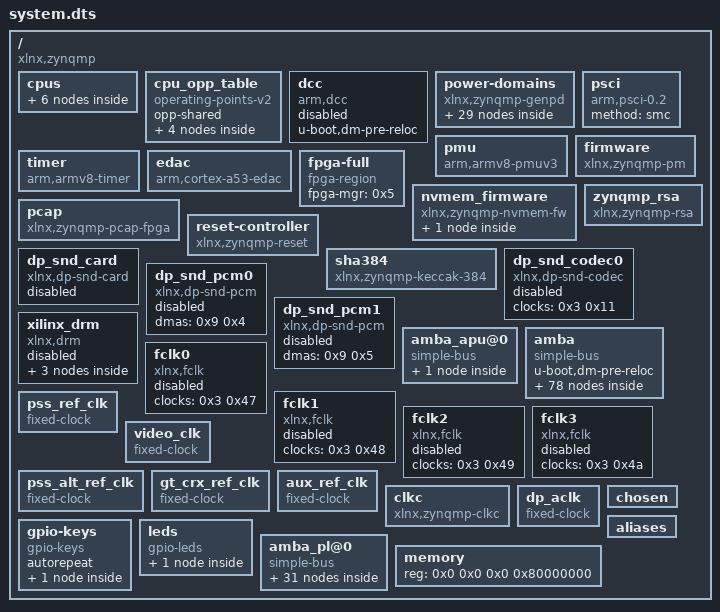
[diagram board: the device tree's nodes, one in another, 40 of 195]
/dts-v1/;

/ {
	compatible = "xlnx,zynqmp";
	#address-cells = <0x2>;
	#size-cells = <0x2>;

	cpus {
		#address-cells = <0x1>;
		#size-cells = <0x0>;

		cpu@0 {
			compatible = "arm,cortex-a53", "arm,armv8";
			device_type = "cpu";
			enable-method = "psci";
			operating-points-v2 = <0x1>;
			reg = <0x0>;
			cpu-idle-states = <0x2>;
			clocks = <0x3 0xa>;
		};

		cpu@1 {
			compatible = "arm,cortex-a53", "arm,armv8";
			device_type = "cpu";
			enable-method = "psci";
			reg = <0x1>;
			operating-points-v2 = <0x1>;
			cpu-idle-states = <0x2>;
		};

		cpu@2 {
			compatible = "arm,cortex-a53", "arm,armv8";
			device_type = "cpu";
			enable-method = "psci";
			reg = <0x2>;
			operating-points-v2 = <0x1>;
			cpu-idle-states = <0x2>;
		};

		cpu@3 {
			compatible = "arm,cortex-a53", "arm,armv8";
			device_type = "cpu";
			enable-method = "psci";
			reg = <0x3>;
			operating-points-v2 = <0x1>;
			cpu-idle-states = <0x2>;
		};

		idle-states {
			entry-method = "arm,psci";

			cpu-sleep-0 {
				compatible = "arm,idle-state";
				arm,psci-suspend-param = <0x40000000>;
				local-timer-stop;
				entry-latency-us = <0x12c>;
				exit-latency-us = <0x258>;
				min-residency-us = <0x2710>;
				linux,phandle = <0x2>;
				phandle = <0x2>;
			};
		};
	};

	cpu_opp_table {
		compatible = "operating-points-v2";
		opp-shared;
		linux,phandle = <0x1>;
		phandle = <0x1>;

		opp00 {
			opp-hz = <0x0 0x47868bf4>;
			opp-microvolt = <0xf4240>;
			clock-latency-ns = <0x7a120>;
		};

		opp01 {
			opp-hz = <0x0 0x23c345fa>;
			opp-microvolt = <0xf4240>;
			clock-latency-ns = <0x7a120>;
		};

		opp02 {
			opp-hz = <0x0 0x17d783fc>;
			opp-microvolt = <0xf4240>;
			clock-latency-ns = <0x7a120>;
		};

		opp03 {
			opp-hz = <0x0 0x11e1a2fd>;
			opp-microvolt = <0xf4240>;
			clock-latency-ns = <0x7a120>;
		};
	};

	dcc {
		compatible = "arm,dcc";
		status = "disabled";
		u-boot,dm-pre-reloc;
	};

	power-domains {
		compatible = "xlnx,zynqmp-genpd";

		pd-usb0 {
			#power-domain-cells = <0x0>;
			pd-id = <0x16>;
			linux,phandle = <0x38>;
			phandle = <0x38>;
		};

		pd-usb1 {
			#power-domain-cells = <0x0>;
			pd-id = <0x17>;
			linux,phandle = <0x3b>;
			phandle = <0x3b>;
		};

		pd-sata {
			#power-domain-cells = <0x0>;
			pd-id = <0x1c>;
			linux,phandle = <0x29>;
			phandle = <0x29>;
		};

		pd-spi0 {
			#power-domain-cells = <0x0>;
			pd-id = <0x23>;
			linux,phandle = <0x2e>;
			phandle = <0x2e>;
		};

		pd-spi1 {
			#power-domain-cells = <0x0>;
			pd-id = <0x24>;
			linux,phandle = <0x2f>;
			phandle = <0x2f>;
		};

		pd-uart0 {
			#power-domain-cells = <0x0>;
			pd-id = <0x21>;
			linux,phandle = <0x34>;
			phandle = <0x34>;
		};

		pd-uart1 {
			#power-domain-cells = <0x0>;
			pd-id = <0x22>;
			linux,phandle = <0x36>;
			phandle = <0x36>;
		};

		pd-eth0 {
			#power-domain-cells = <0x0>;
			pd-id = <0x1d>;
			linux,phandle = <0x14>;
			phandle = <0x14>;
		};

		pd-eth1 {
			#power-domain-cells = <0x0>;
			pd-id = <0x1e>;
			linux,phandle = <0x15>;
			phandle = <0x15>;
		};

		pd-eth2 {
			#power-domain-cells = <0x0>;
			pd-id = <0x1f>;
			linux,phandle = <0x16>;
			phandle = <0x16>;
		};

		pd-eth3 {
			#power-domain-cells = <0x0>;
			pd-id = <0x20>;
			linux,phandle = <0x17>;
			phandle = <0x17>;
		};

		pd-i2c0 {
			#power-domain-cells = <0x0>;
			pd-id = <0x25>;
			linux,phandle = <0x1c>;
			phandle = <0x1c>;
		};

		pd-i2c1 {
			#power-domain-cells = <0x0>;
			pd-id = <0x26>;
			linux,phandle = <0x20>;
			phandle = <0x20>;
		};

		pd-dp {
			#power-domain-cells = <0x0>;
			pd-id = <0x29>;
			linux,phandle = <0x3c>;
			phandle = <0x3c>;
		};

		pd-gdma {
			#power-domain-cells = <0x0>;
			pd-id = <0x2a>;
			linux,phandle = <0x10>;
			phandle = <0x10>;
		};

		pd-adma {
			#power-domain-cells = <0x0>;
			pd-id = <0x2b>;
			linux,phandle = <0x12>;
			phandle = <0x12>;
		};

		pd-ttc0 {
			#power-domain-cells = <0x0>;
			pd-id = <0x18>;
			linux,phandle = <0x30>;
			phandle = <0x30>;
		};

		pd-ttc1 {
			#power-domain-cells = <0x0>;
			pd-id = <0x19>;
			linux,phandle = <0x31>;
			phandle = <0x31>;
		};

		pd-ttc2 {
			#power-domain-cells = <0x0>;
			pd-id = <0x1a>;
			linux,phandle = <0x32>;
			phandle = <0x32>;
		};

		pd-ttc3 {
			#power-domain-cells = <0x0>;
			pd-id = <0x1b>;
			linux,phandle = <0x33>;
			phandle = <0x33>;
		};

		pd-sd0 {
			#power-domain-cells = <0x0>;
			pd-id = <0x27>;
			linux,phandle = <0x2b>;
			phandle = <0x2b>;
		};

		pd-sd1 {
			#power-domain-cells = <0x0>;
			pd-id = <0x28>;
			linux,phandle = <0x2c>;
			phandle = <0x2c>;
		};

		pd-nand {
			#power-domain-cells = <0x0>;
			pd-id = <0x2c>;
			linux,phandle = <0x13>;
			phandle = <0x13>;
		};

		pd-qspi {
			#power-domain-cells = <0x0>;
			pd-id = <0x2d>;
			linux,phandle = <0x26>;
			phandle = <0x26>;
		};

		pd-gpio {
			#power-domain-cells = <0x0>;
			pd-id = <0x2e>;
			linux,phandle = <0x1a>;
			phandle = <0x1a>;
		};

		pd-can0 {
			#power-domain-cells = <0x0>;
			pd-id = <0x2f>;
			linux,phandle = <0xc>;
			phandle = <0xc>;
		};

		pd-can1 {
			#power-domain-cells = <0x0>;
			pd-id = <0x30>;
			linux,phandle = <0xd>;
			phandle = <0xd>;
		};

		pd-pcie {
			#power-domain-cells = <0x0>;
			pd-id = <0x3b>;
			linux,phandle = <0x25>;
			phandle = <0x25>;
		};

		pd-gpu {
			#power-domain-cells = <0x0>;
			pd-id = <0x3a 0x14 0x15>;
			linux,phandle = <0x11>;
			phandle = <0x11>;
		};
	};

	pmu {
		compatible = "arm,armv8-pmuv3";
		interrupt-parent = <0x4>;
		interrupts = <0x0 0x8f 0x4 0x0 0x90 0x4 0x0 0x91 0x4 0x0 0x92 0x4>;
	};

	psci {
		compatible = "arm,psci-0.2";
		method = "smc";
	};

	firmware {
		compatible = "xlnx,zynqmp-pm";
		method = "smc";
		interrupt-parent = <0x4>;
		interrupts = <0x0 0x23 0x4>;
	};

	timer {
		compatible = "arm,armv8-timer";
		interrupt-parent = <0x4>;
		interrupts = <0x1 0xd 0xf08 0x1 0xe 0xf08 0x1 0xb 0xf08 0x1 0xa 0xf08>;
	};

	edac {
		compatible = "arm,cortex-a53-edac";
	};

	fpga-full {
		compatible = "fpga-region";
		fpga-mgr = <0x5>;
		#address-cells = <0x2>;
		#size-cells = <0x2>;
	};

	nvmem_firmware {
		compatible = "xlnx,zynqmp-nvmem-fw";
		#address-cells = <0x1>;
		#size-cells = <0x1>;

		soc_revision@0 {
			reg = <0x0 0x4>;
			linux,phandle = <0x27>;
			phandle = <0x27>;
		};
	};

	pcap {
		compatible = "xlnx,zynqmp-pcap-fpga";
		linux,phandle = <0x5>;
		phandle = <0x5>;
	};

	reset-controller {
		compatible = "xlnx,zynqmp-reset";
		#reset-cells = <0x1>;
		linux,phandle = <0x28>;
		phandle = <0x28>;
	};

	zynqmp_rsa {
		compatible = "xlnx,zynqmp-rsa";
	};

	sha384 {
		compatible = "xlnx,zynqmp-keccak-384";
	};

	dp_snd_card {
		compatible = "xlnx,dp-snd-card";
		status = "disabled";
		xlnx,dp-snd-pcm = <0x6 0x7>;
		xlnx,dp-snd-codec = <0x8>;
	};

	dp_snd_codec0 {
		compatible = "xlnx,dp-snd-codec";
		status = "disabled";
		clock-names = "aud_clk";
		clocks = <0x3 0x11>;
		linux,phandle = <0x8>;
		phandle = <0x8>;
	};

	dp_snd_pcm0 {
		compatible = "xlnx,dp-snd-pcm";
		status = "disabled";
		dmas = <0x9 0x4>;
		dma-names = "tx";
		linux,phandle = <0x6>;
		phandle = <0x6>;
	};

	dp_snd_pcm1 {
		compatible = "xlnx,dp-snd-pcm";
		status = "disabled";
		dmas = <0x9 0x5>;
		dma-names = "tx";
		linux,phandle = <0x7>;
		phandle = <0x7>;
	};

	xilinx_drm {
		compatible = "xlnx,drm";
		status = "disabled";
		xlnx,encoder-slave = <0xa>;
		xlnx,connector-type = "DisplayPort";
		xlnx,dp-sub = <0xb>;
		clocks = <0x3 0x10>;

		planes {
			xlnx,pixel-format = "rgb565";

			plane0 {
				dmas = <0x9 0x3>;
				dma-names = "dma0";
			};

			plane1 {
				dmas = <0x9 0x0 0x9 0x1 0x9 0x2>;
				dma-names = "dma0", "dma1", "dma2";
			};
		};
	};

	amba_apu@0 {
		compatible = "simple-bus";
		#address-cells = <0x2>;
		#size-cells = <0x1>;
		ranges = <0x0 0x0 0x0 0x0 0xffffffff>;

		interrupt-controller@f9010000 {
			compatible = "arm,gic-400", "arm,cortex-a15-gic";
			#interrupt-cells = <0x3>;
			reg = <0x0 0xf9010000 0x10000 0x0 0xf9020000 0x20000 0x0 0xf9040000 0x20000 0x0 0xf9060000 0x20000>;
			interrupt-controller;
			interrupt-parent = <0x4>;
			interrupts = <0x1 0x9 0xf04>;
			linux,phandle = <0x4>;
			phandle = <0x4>;
		};
	};

	amba {
		compatible = "simple-bus";
		u-boot,dm-pre-reloc;
		#address-cells = <0x2>;
		#size-cells = <0x2>;
		ranges;

		can@ff060000 {
			compatible = "xlnx,zynq-can-1.0";
			status = "disabled";
			clock-names = "can_clk", "pclk";
			reg = <0x0 0xff060000 0x0 0x1000>;
			interrupts = <0x0 0x17 0x4>;
			interrupt-parent = <0x4>;
			tx-fifo-depth = <0x40>;
			rx-fifo-depth = <0x40>;
			power-domains = <0xc>;
			clocks = <0x3 0x3f 0x3 0x1f>;
		};

		can@ff070000 {
			compatible = "xlnx,zynq-can-1.0";
			status = "disabled";
			clock-names = "can_clk", "pclk";
			reg = <0x0 0xff070000 0x0 0x1000>;
			interrupts = <0x0 0x18 0x4>;
			interrupt-parent = <0x4>;
			tx-fifo-depth = <0x40>;
			rx-fifo-depth = <0x40>;
			power-domains = <0xd>;
			clocks = <0x3 0x40 0x3 0x1f>;
		};

		cci@fd6e0000 {
			compatible = "arm,cci-400";
			reg = <0x0 0xfd6e0000 0x0 0x9000>;
			ranges = <0x0 0x0 0xfd6e0000 0x10000>;
			#address-cells = <0x1>;
			#size-cells = <0x1>;

			pmu@9000 {
				compatible = "arm,cci-400-pmu,r1";
				reg = <0x9000 0x5000>;
				interrupt-parent = <0x4>;
				interrupts = <0x0 0x7b 0x4 0x0 0x7b 0x4 0x0 0x7b 0x4 0x0 0x7b 0x4 0x0 0x7b 0x4>;
			};
		};

		dma@fd500000 {
			status = "okay";
			compatible = "xlnx,zynqmp-dma-1.0";
			reg = <0x0 0xfd500000 0x0 0x1000>;
			interrupt-parent = <0x4>;
			interrupts = <0x0 0x7c 0x4>;
			clock-names = "clk_main", "clk_apb";
			xlnx,bus-width = <0x80>;
			#stream-id-cells = <0x1>;
			iommus = <0xf 0x14e8>;
			power-domains = <0x10>;
			clocks = <0x3 0x13 0x3 0x1f>;
		};

		dma@fd510000 {
			status = "okay";
			compatible = "xlnx,zynqmp-dma-1.0";
			reg = <0x0 0xfd510000 0x0 0x1000>;
			interrupt-parent = <0x4>;
			interrupts = <0x0 0x7d 0x4>;
			clock-names = "clk_main", "clk_apb";
			xlnx,bus-width = <0x80>;
			#stream-id-cells = <0x1>;
			iommus = <0xf 0x14e9>;
			power-domains = <0x10>;
			clocks = <0x3 0x13 0x3 0x1f>;
		};

		dma@fd520000 {
			status = "okay";
			compatible = "xlnx,zynqmp-dma-1.0";
			reg = <0x0 0xfd520000 0x0 0x1000>;
			interrupt-parent = <0x4>;
			interrupts = <0x0 0x7e 0x4>;
			clock-names = "clk_main", "clk_apb";
			xlnx,bus-width = <0x80>;
			#stream-id-cells = <0x1>;
			iommus = <0xf 0x14ea>;
			power-domains = <0x10>;
			clocks = <0x3 0x13 0x3 0x1f>;
		};

		dma@fd530000 {
			status = "okay";
			compatible = "xlnx,zynqmp-dma-1.0";
			reg = <0x0 0xfd530000 0x0 0x1000>;
			interrupt-parent = <0x4>;
			interrupts = <0x0 0x7f 0x4>;
			clock-names = "clk_main", "clk_apb";
			xlnx,bus-width = <0x80>;
			#stream-id-cells = <0x1>;
			iommus = <0xf 0x14eb>;
			power-domains = <0x10>;
			clocks = <0x3 0x13 0x3 0x1f>;
		};

		dma@fd540000 {
			status = "okay";
			compatible = "xlnx,zynqmp-dma-1.0";
			reg = <0x0 0xfd540000 0x0 0x1000>;
			interrupt-parent = <0x4>;
			interrupts = <0x0 0x80 0x4>;
			clock-names = "clk_main", "clk_apb";
			xlnx,bus-width = <0x80>;
			#stream-id-cells = <0x1>;
			iommus = <0xf 0x14ec>;
			power-domains = <0x10>;
			clocks = <0x3 0x13 0x3 0x1f>;
		};

		dma@fd550000 {
			status = "okay";
			compatible = "xlnx,zynqmp-dma-1.0";
			reg = <0x0 0xfd550000 0x0 0x1000>;
			interrupt-parent = <0x4>;
			interrupts = <0x0 0x81 0x4>;
			clock-names = "clk_main", "clk_apb";
			xlnx,bus-width = <0x80>;
			#stream-id-cells = <0x1>;
			iommus = <0xf 0x14ed>;
			power-domains = <0x10>;
			clocks = <0x3 0x13 0x3 0x1f>;
		};

		dma@fd560000 {
			status = "okay";
			compatible = "xlnx,zynqmp-dma-1.0";
			reg = <0x0 0xfd560000 0x0 0x1000>;
			interrupt-parent = <0x4>;
			interrupts = <0x0 0x82 0x4>;
			clock-names = "clk_main", "clk_apb";
			xlnx,bus-width = <0x80>;
			#stream-id-cells = <0x1>;
			iommus = <0xf 0x14ee>;
			power-domains = <0x10>;
			clocks = <0x3 0x13 0x3 0x1f>;
		};

		dma@fd570000 {
			status = "okay";
			compatible = "xlnx,zynqmp-dma-1.0";
			reg = <0x0 0xfd570000 0x0 0x1000>;
			interrupt-parent = <0x4>;
			interrupts = <0x0 0x83 0x4>;
			clock-names = "clk_main", "clk_apb";
			xlnx,bus-width = <0x80>;
			#stream-id-cells = <0x1>;
			iommus = <0xf 0x14ef>;
			power-domains = <0x10>;
			clocks = <0x3 0x13 0x3 0x1f>;
		};

		gpu@fd4b0000 {
			status = "okay";
			compatible = "arm,mali-400", "arm,mali-utgard";
			reg = <0x0 0xfd4b0000 0x0 0x10000>;
			interrupt-parent = <0x4>;
			interrupts = <0x0 0x84 0x4 0x0 0x84 0x4 0x0 0x84 0x4 0x0 0x84 0x4 0x0 0x84 0x4 0x0 0x84 0x4>;
			interrupt-names = "IRQGP", "IRQGPMMU", "IRQPP0", "IRQPPMMU0", "IRQPP1", "IRQPPMMU1";
			clock-names = "gpu", "gpu_pp0", "gpu_pp1";
			power-domains = <0x11>;
			clocks = <0x3 0x18 0x3 0x19 0x3 0x1a>;
		};

		dma@ffa80000 {
			status = "okay";
			compatible = "xlnx,zynqmp-dma-1.0";
			clock-names = "clk_main", "clk_apb";
			reg = <0x0 0xffa80000 0x0 0x1000>;
			interrupt-parent = <0x4>;
			interrupts = <0x0 0x4d 0x4>;
			xlnx,bus-width = <0x40>;
			#stream-id-cells = <0x1>;
			power-domains = <0x12>;
			clocks = <0x3 0x44 0x3 0x1f>;
		};

		dma@ffa90000 {
			status = "okay";
			compatible = "xlnx,zynqmp-dma-1.0";
			clock-names = "clk_main", "clk_apb";
			reg = <0x0 0xffa90000 0x0 0x1000>;
			interrupt-parent = <0x4>;
			interrupts = <0x0 0x4e 0x4>;
			xlnx,bus-width = <0x40>;
			#stream-id-cells = <0x1>;
			power-domains = <0x12>;
			clocks = <0x3 0x44 0x3 0x1f>;
		};

		dma@ffaa0000 {
			status = "okay";
			compatible = "xlnx,zynqmp-dma-1.0";
			clock-names = "clk_main", "clk_apb";
			reg = <0x0 0xffaa0000 0x0 0x1000>;
			interrupt-parent = <0x4>;
			interrupts = <0x0 0x4f 0x4>;
			xlnx,bus-width = <0x40>;
			#stream-id-cells = <0x1>;
			power-domains = <0x12>;
			clocks = <0x3 0x44 0x3 0x1f>;
		};

		dma@ffab0000 {
			status = "okay";
			compatible = "xlnx,zynqmp-dma-1.0";
			clock-names = "clk_main", "clk_apb";
			reg = <0x0 0xffab0000 0x0 0x1000>;
			interrupt-parent = <0x4>;
			interrupts = <0x0 0x50 0x4>;
			xlnx,bus-width = <0x40>;
			#stream-id-cells = <0x1>;
			power-domains = <0x12>;
			clocks = <0x3 0x44 0x3 0x1f>;
		};

		dma@ffac0000 {
			status = "okay";
			compatible = "xlnx,zynqmp-dma-1.0";
			clock-names = "clk_main", "clk_apb";
			reg = <0x0 0xffac0000 0x0 0x1000>;
			interrupt-parent = <0x4>;
			interrupts = <0x0 0x51 0x4>;
			xlnx,bus-width = <0x40>;
			#stream-id-cells = <0x1>;
			power-domains = <0x12>;
			clocks = <0x3 0x44 0x3 0x1f>;
		};

		dma@ffad0000 {
			status = "okay";
			compatible = "xlnx,zynqmp-dma-1.0";
			clock-names = "clk_main", "clk_apb";
			reg = <0x0 0xffad0000 0x0 0x1000>;
			interrupt-parent = <0x4>;
			interrupts = <0x0 0x52 0x4>;
			xlnx,bus-width = <0x40>;
			#stream-id-cells = <0x1>;
			power-domains = <0x12>;
			clocks = <0x3 0x44 0x3 0x1f>;
		};

		dma@ffae0000 {
			status = "okay";
			compatible = "xlnx,zynqmp-dma-1.0";
			clock-names = "clk_main", "clk_apb";
			reg = <0x0 0xffae0000 0x0 0x1000>;
			interrupt-parent = <0x4>;
			interrupts = <0x0 0x53 0x4>;
			xlnx,bus-width = <0x40>;
			#stream-id-cells = <0x1>;
			power-domains = <0x12>;
			clocks = <0x3 0x44 0x3 0x1f>;
		};

		dma@ffaf0000 {
			status = "okay";
			compatible = "xlnx,zynqmp-dma-1.0";
			clock-names = "clk_main", "clk_apb";
			reg = <0x0 0xffaf0000 0x0 0x1000>;
			interrupt-parent = <0x4>;
			interrupts = <0x0 0x54 0x4>;
			xlnx,bus-width = <0x40>;
			#stream-id-cells = <0x1>;
			power-domains = <0x12>;
			clocks = <0x3 0x44 0x3 0x1f>;
		};

		memory-controller@fd070000 {
			compatible = "xlnx,zynqmp-ddrc-2.40a";
			reg = <0x0 0xfd070000 0x0 0x30000>;
			interrupt-parent = <0x4>;
			interrupts = <0x0 0x70 0x4>;
		};

		nand@ff100000 {
			compatible = "arasan,nfc-v3p10";
			status = "disabled";
			reg = <0x0 0xff100000 0x0 0x1000>;
			clock-names = "clk_sys", "clk_flash";
			interrupt-parent = <0x4>;
			interrupts = <0x0 0xe 0x4>;
			#address-cells = <0x1>;
			#size-cells = <0x0>;
			#stream-id-cells = <0x1>;
			iommus = <0xf 0x872>;
			power-domains = <0x13>;
			clocks = <0x3 0x3c 0x3 0x1f>;
		};

		ethernet@ff0b0000 {
			compatible = "cdns,zynqmp-gem";
			status = "okay";
			interrupt-parent = <0x4>;
			interrupts = <0x0 0x39 0x4 0x0 0x39 0x4>;
			reg = <0x0 0xff0b0000 0x0 0x1000>;
			clock-names = "pclk", "tx_clk", "hclk";
			#address-cells = <0x1>;
			#size-cells = <0x0>;
			#stream-id-cells = <0x1>;
			iommus = <0xf 0x874>;
			power-domains = <0x14>;
			clocks = <0x3 0x2d 0x3 0x2d 0x3 0x31>;
			phy-mode = "rgmii-id";
			xlnx,ptp-enet-clock = <0x0>;
			local-mac-address = [00 0a 35 00 22 01];
		};

		ethernet@ff0c0000 {
			compatible = "cdns,zynqmp-gem";
			status = "disabled";
			interrupt-parent = <0x4>;
			interrupts = <0x0 0x3b 0x4 0x0 0x3b 0x4>;
			reg = <0x0 0xff0c0000 0x0 0x1000>;
			clock-names = "pclk", "tx_clk", "hclk";
			#address-cells = <0x1>;
			#size-cells = <0x0>;
			#stream-id-cells = <0x1>;
			iommus = <0xf 0x875>;
			power-domains = <0x15>;
			clocks = <0x3 0x2e 0x3 0x2e 0x3 0x32>;
		};

		ethernet@ff0d0000 {
			compatible = "cdns,zynqmp-gem";
			status = "disabled";
			interrupt-parent = <0x4>;
			interrupts = <0x0 0x3d 0x4 0x0 0x3d 0x4>;
			reg = <0x0 0xff0d0000 0x0 0x1000>;
			clock-names = "pclk", "tx_clk", "hclk";
			#address-cells = <0x1>;
			#size-cells = <0x0>;
			#stream-id-cells = <0x1>;
			iommus = <0xf 0x876>;
			power-domains = <0x16>;
			clocks = <0x3 0x2f 0x3 0x2f 0x3 0x33>;
		};

		ethernet@ff0e0000 {
			compatible = "cdns,zynqmp-gem";
			status = "disabled";
			interrupt-parent = <0x4>;
			interrupts = <0x0 0x3f 0x4 0x0 0x3f 0x4>;
			reg = <0x0 0xff0e0000 0x0 0x1000>;
			clock-names = "pclk", "hclk", "tx_clk", "rx_clk";
			#address-cells = <0x1>;
			#size-cells = <0x0>;
			#stream-id-cells = <0x1>;
			iommus = <0xf 0x877>;
			power-domains = <0x17>;
			clocks = <0x3 0x1f 0x3 0x34 0x3 0x30 0x3 0x34>;
		};

		gpio@ff0a0000 {
			compatible = "xlnx,zynqmp-gpio-1.0";
			status = "disabled";
			#gpio-cells = <0x2>;
			interrupt-parent = <0x4>;
			interrupts = <0x0 0x10 0x4>;
			interrupt-controller;
			#interrupt-cells = <0x2>;
			reg = <0x0 0xff0a0000 0x0 0x1000>;
			gpio-controller;
			power-domains = <0x1a>;
			clocks = <0x3 0x1f>;
			emio-gpio-width = <0x20>;
			gpio-mask-high = <0x0>;
			gpio-mask-low = <0x5600>;
			linux,phandle = <0x1f>;
			phandle = <0x1f>;
		};

		i2c@ff020000 {
			compatible = "cdns,i2c-r1p14", "cdns,i2c-r1p10";
			status = "okay";
			interrupt-parent = <0x4>;
			interrupts = <0x0 0x11 0x4>;
			reg = <0x0 0xff020000 0x0 0x1000>;
			#address-cells = <0x1>;
			#size-cells = <0x0>;
			power-domains = <0x1c>;
			clocks = <0x3 0x3d>;
			clock-frequency = <0x171ec>;
		};

		i2c@ff030000 {
			compatible = "cdns,i2c-r1p14", "cdns,i2c-r1p10";
			status = "okay";
			interrupt-parent = <0x4>;
			interrupts = <0x0 0x12 0x4>;
			reg = <0x0 0xff030000 0x0 0x1000>;
			#address-cells = <0x1>;
			#size-cells = <0x0>;
			power-domains = <0x20>;
			clocks = <0x3 0x3e>;
			clock-frequency = <0x15c0c>;
		};

		memory-controller@ff960000 {
			compatible = "xlnx,zynqmp-ocmc-1.0";
			reg = <0x0 0xff960000 0x0 0x1000>;
			interrupt-parent = <0x4>;
			interrupts = <0x0 0xa 0x4>;
		};

		pcie@fd0e0000 {
			compatible = "xlnx,nwl-pcie-2.11";
			status = "disabled";
			#address-cells = <0x3>;
			#size-cells = <0x2>;
			#interrupt-cells = <0x1>;
			msi-controller;
			device_type = "pci";
			interrupt-parent = <0x4>;
			interrupts = <0x0 0x76 0x4 0x0 0x75 0x4 0x0 0x74 0x4 0x0 0x73 0x4 0x0 0x72 0x4>;
			interrupt-names = "misc", "dummy", "intx", "msi1", "msi0";
			msi-parent = <0x23>;
			reg = <0x0 0xfd0e0000 0x0 0x1000 0x0 0xfd480000 0x0 0x1000 0x80 0x0 0x0 0x1000000>;
			reg-names = "breg", "pcireg", "cfg";
			ranges = <0x2000000 0x0 0xe0000000 0x0 0xe0000000 0x0 0x10000000 0x43000000 0x6 0x0 0x6 0x0 0x2 0x0>;
			interrupt-map-mask = <0x0 0x0 0x0 0x7>;
			bus-range = <0x0 0xff>;
			interrupt-map = <0x0 0x0 0x0 0x1 0x24 0x1 0x0 0x0 0x0 0x2 0x24 0x2 0x0 0x0 0x0 0x3 0x24 0x3 0x0 0x0 0x0 0x4 0x24 0x4>;
			power-domains = <0x25>;
			clocks = <0x3 0x17>;
			linux,phandle = <0x23>;
			phandle = <0x23>;

			legacy-interrupt-controller {
				interrupt-controller;
				#address-cells = <0x0>;
				#interrupt-cells = <0x1>;
				linux,phandle = <0x24>;
				phandle = <0x24>;
			};
		};

		spi@ff0f0000 {
			u-boot,dm-pre-reloc;
			compatible = "xlnx,zynqmp-qspi-1.0";
			status = "okay";
			clock-names = "ref_clk", "pclk";
			interrupts = <0x0 0xf 0x4>;
			interrupt-parent = <0x4>;
			num-cs = <0x1>;
			reg = <0x0 0xff0f0000 0x0 0x1000 0x0 0xc0000000 0x0 0x8000000>;
			#address-cells = <0x1>;
			#size-cells = <0x0>;
			#stream-id-cells = <0x1>;
			iommus = <0xf 0x873>;
			power-domains = <0x26>;
			clocks = <0x3 0x35 0x3 0x1f>;
			is-dual = <0x1>;
			spi-rx-bus-width = <0x4>;
			spi-tx-bus-width = <0x4>;

			flash@0 {
				compatible = "mx66u1g45g", "micron,m25p80";
				#address-cells = <0x1>;
				#size-cells = <0x1>;
				reg = <0x0>;
				spi-tx-bus-width = <0x1>;
				spi-rx-bus-width = <0x4>;
				spi-max-frequency = <0x2faf080>;
			};
		};

		rtc@ffa60000 {
			compatible = "xlnx,zynqmp-rtc";
			status = "okay";
			reg = <0x0 0xffa60000 0x0 0x100>;
			interrupt-parent = <0x4>;
			interrupts = <0x0 0x1a 0x4 0x0 0x1b 0x4>;
			interrupt-names = "alarm", "sec";
			calibration = <0x8000>;
		};

		zynqmp_phy@fd400000 {
			compatible = "xlnx,zynqmp-psgtr";
			status = "okay";
			reg = <0x0 0xfd400000 0x0 0x40000 0x0 0xfd3d0000 0x0 0x1000 0x0 0xff5e0000 0x0 0x1000>;
			reg-names = "serdes", "siou", "lpd";
			nvmem-cells = <0x27>;
			nvmem-cell-names = "soc_revision";
			resets = <0x28 0x10 0x28 0x3b 0x28 0x3c 0x28 0x3d 0x28 0x3e 0x28 0x3f 0x28 0x40 0x28 0x3 0x28 0x1d 0x28 0x1e 0x28 0x1f 0x28 0x20>;
			reset-names = "sata_rst", "usb0_crst", "usb1_crst", "usb0_hibrst", "usb1_hibrst", "usb0_apbrst", "usb1_apbrst", "dp_rst", "gem0_rst", "gem1_rst", "gem2_rst", "gem3_rst";

			lane0 {
				#phy-cells = <0x4>;
			};

			lane1 {
				#phy-cells = <0x4>;
			};

			lane2 {
				#phy-cells = <0x4>;
				linux,phandle = <0x3a>;
				phandle = <0x3a>;
			};

			lane3 {
				#phy-cells = <0x4>;
				linux,phandle = <0x2a>;
				phandle = <0x2a>;
			};
		};

		ahci@fd0c0000 {
			compatible = "ceva,ahci-1v84";
			status = "disabled";
			reg = <0x0 0xfd0c0000 0x0 0x2000>;
			interrupt-parent = <0x4>;
			interrupts = <0x0 0x85 0x4>;
			power-domains = <0x29>;
			#stream-id-cells = <0x4>;
			iommus = <0xf 0x4c0 0xf 0x4c1 0xf 0x4c2 0xf 0x4c3>;
			clocks = <0x3 0x16>;
			ceva,p0-cominit-params = <0x18401828>;
			ceva,p0-comwake-params = <0x614080e>;
			ceva,p0-burst-params = <0x13084a06>;
			ceva,p0-retry-params = <0x96a43ffc>;
			ceva,p1-cominit-params = <0x18401828>;
			ceva,p1-comwake-params = <0x614080e>;
			ceva,p1-burst-params = <0x13084a06>;
			ceva,p1-retry-params = <0x96a43ffc>;
			phy-names = "sata-phy";
			phys = <0x2a 0x1 0x1 0x1 0x7735940>;
		};

		sdhci@ff160000 {
			u-boot,dm-pre-reloc;
			compatible = "xlnx,zynqmp-8.9a", "arasan,sdhci-8.9a";
			status = "disabled";
			interrupt-parent = <0x4>;
			interrupts = <0x0 0x30 0x4>;
			reg = <0x0 0xff160000 0x0 0x1000>;
			clock-names = "clk_xin", "clk_ahb";
			xlnx,device_id = <0x0>;
			#stream-id-cells = <0x1>;
			iommus = <0xf 0x870>;
			power-domains = <0x2b>;
			clocks = <0x3 0x36 0x3 0x1f>;
		};

		sdhci@ff170000 {
			u-boot,dm-pre-reloc;
			compatible = "xlnx,zynqmp-8.9a", "arasan,sdhci-8.9a";
			status = "disabled";
			interrupt-parent = <0x4>;
			interrupts = <0x0 0x31 0x4>;
			reg = <0x0 0xff170000 0x0 0x1000>;
			clock-names = "clk_xin", "clk_ahb";
			xlnx,device_id = <0x1>;
			#stream-id-cells = <0x1>;
			iommus = <0xf 0x871>;
			power-domains = <0x2c>;
			clocks = <0x3 0x37 0x3 0x1f>;
			clock-frequency = <0xbebc200>;
			xlnx,mio_bank = <0x1>;
		};

		pinctrl@ff180000 {
			compatible = "xlnx,pinctrl-zynqmp";
			status = "okay";
			reg = <0x0 0xff180000 0x0 0x1000>;
		};

		smmu@fd800000 {
			compatible = "arm,mmu-500";
			reg = <0x0 0xfd800000 0x0 0x20000>;
			#iommu-cells = <0x1>;
			status = "disabled";
			#global-interrupts = <0x1>;
			interrupt-parent = <0x4>;
			interrupts = <0x0 0x9b 0x4 0x0 0x9b 0x4 0x0 0x9b 0x4 0x0 0x9b 0x4 0x0 0x9b 0x4 0x0 0x9b 0x4 0x0 0x9b 0x4 0x0 0x9b 0x4 0x0 0x9b 0x4 0x0 0x9b 0x4 0x0 0x9b 0x4 0x0 0x9b 0x4 0x0 0x9b 0x4 0x0 0x9b 0x4 0x0 0x9b 0x4 0x0 0x9b 0x4 0x0 0x9b 0x4>;
			linux,phandle = <0xf>;
			phandle = <0xf>;
		};

		spi@ff040000 {
			compatible = "cdns,spi-r1p6";
			status = "okay";
			interrupt-parent = <0x4>;
			interrupts = <0x0 0x13 0x4>;
			reg = <0x0 0xff040000 0x0 0x1000>;
			clock-names = "ref_clk", "pclk";
			#address-cells = <0x1>;
			#size-cells = <0x0>;
			power-domains = <0x2e>;
			clocks = <0x3 0x3a 0x3 0x1f>;
			is-decoded-cs = <0x0>;
			num-cs = <0x3>;

			spidev@0 {
				compatible = "rohm,dh2228fv";
				reg = <0>;	/* chip select */
				spi-max-frequency = <12500000>;
				#address-cells = <1>;
				#size-cells = <1>;
			};
		
			spidev@1 {
				compatible = "rohm,dh2228fv";
				reg = <1>;	/* chip select */
				spi-max-frequency = <12500000>;
				#address-cells = <1>;
				#size-cells = <1>;
			};

			spidev@2 {
				compatible = "rohm,dh2228fv";
				reg = <2>;	/* chip select */
				spi-max-frequency = <12500000>;
				#address-cells = <1>;
				#size-cells = <1>;
			};

		};

		spi@ff050000 {
			compatible = "cdns,spi-r1p6";
			status = "okay";
			interrupt-parent = <0x4>;
			interrupts = <0x0 0x14 0x4>;
			reg = <0x0 0xff050000 0x0 0x1000>;
			clock-names = "ref_clk", "pclk";
			#address-cells = <0x1>;
			#size-cells = <0x0>;
			power-domains = <0x2f>;
			clocks = <0x3 0x3b 0x3 0x1f>;
			is-decoded-cs = <0x0>;
			num-cs = <0x2>;

			spidev@0 {
				compatible = "rohm,dh2228fv";
				reg = <0>;	/* chip select */
				spi-max-frequency = <12500000>;
				#address-cells = <1>;
				#size-cells = <1>;
			};
		
			spidev@1 {
				compatible = "rohm,dh2228fv";
				reg = <1>;	/* chip select */
				spi-max-frequency = <12500000>;
				#address-cells = <1>;
				#size-cells = <1>;
			};

		};

		fheth0_m@7FF00000 {
			compatible="fujitsu.fheth";
			reg = <0x0 0xA1000000 0x0 0x0001000 
			       0x0 0xA1010800 0x0 0x0000800 
			       0x0 0xA1024000 0x0 0x0004000
			       0x0 0xA1028000 0x0 0x0000100>;
			interrupt-parent = <0x4>;
			interrupts = <0x0 104 0x4>;
		};

		fheth0_s@7FF00000 {
			compatible="fujitsu.fheth";
			reg = <0x0 0xA1000000 0x0 0x0001000 
			       0x0 0xA1010000 0x0 0x0000800 
			       0x0 0xA1020000 0x0 0x0004000
			       0x0 0xA1028000 0x0 0x0000100>;
			interrupt-parent = <0x4>;
			interrupts = <0x0 106 0x4>;
		};

		timer@ff110000 {
			compatible = "cdns,ttc";
			status = "disabled";
			interrupt-parent = <0x4>;
			interrupts = <0x0 0x24 0x4 0x0 0x25 0x4 0x0 0x26 0x4>;
			reg = <0x0 0xff110000 0x0 0x1000>;
			timer-width = <0x20>;
			power-domains = <0x30>;
		};

		timer@ff120000 {
			compatible = "cdns,ttc";
			status = "disabled";
			interrupt-parent = <0x4>;
			interrupts = <0x0 0x27 0x4 0x0 0x28 0x4 0x0 0x29 0x4>;
			reg = <0x0 0xff120000 0x0 0x1000>;
			timer-width = <0x20>;
			power-domains = <0x31>;
		};

		timer@ff130000 {
			compatible = "cdns,ttc";
			status = "disabled";
			interrupt-parent = <0x4>;
			interrupts = <0x0 0x2a 0x4 0x0 0x2b 0x4 0x0 0x2c 0x4>;
			reg = <0x0 0xff130000 0x0 0x1000>;
			timer-width = <0x20>;
			power-domains = <0x32>;
		};

		timer@ff140000 {
			compatible = "cdns,ttc";
			status = "disabled";
			interrupt-parent = <0x4>;
			interrupts = <0x0 0x2d 0x4 0x0 0x2e 0x4 0x0 0x2f 0x4>;
			reg = <0x0 0xff140000 0x0 0x1000>;
			timer-width = <0x20>;
			power-domains = <0x33>;
		};

		serial@ff000000 {
			u-boot,dm-pre-reloc;
			compatible = "cdns,uart-r1p12", "xlnx,xuartps";
			status = "disabled";
			interrupt-parent = <0x4>;
			interrupts = <0x0 0x15 0x4>;
			reg = <0x0 0xff000000 0x0 0x1000>;
			clock-names = "uart_clk", "pclk";
			power-domains = <0x34>;
			clocks = <0x3 0x38 0x3 0x1f>;
		};

		serial@ff010000 {
			u-boot,dm-pre-reloc;
			compatible = "cdns,uart-r1p12", "xlnx,xuartps";
			status = "okay";
			interrupt-parent = <0x4>;
			interrupts = <0x0 0x16 0x4>;
			reg = <0x0 0xff010000 0x0 0x1000>;
			clock-names = "uart_clk", "pclk";
			power-domains = <0x36>;
			clocks = <0x3 0x39 0x3 0x1f>;
			device_type = "serial";
			port-number = <0x0>;
		};

		usb0@ff9d0000 {
			#address-cells = <0x2>;
			#size-cells = <0x2>;
			status = "disabled";
			compatible = "xlnx,zynqmp-dwc3";
			reg = <0x0 0xff9d0000 0x0 0x100>;
			clock-names = "bus_clk", "ref_clk";
			power-domains = <0x38>;
			ranges;
			nvmem-cells = <0x27>;
			nvmem-cell-names = "soc_revision";
			clocks = <0x3 0x20 0x3 0x22>;

			dwc3@fe200000 {
				compatible = "snps,dwc3";
				status = "disabled";
				reg = <0x0 0xfe200000 0x0 0x40000>;
				interrupt-parent = <0x4>;
				interrupts = <0x0 0x41 0x4 0x0 0x45 0x4>;
				#stream-id-cells = <0x1>;
				iommus = <0xf 0x860>;
				snps,quirk-frame-length-adjustment = <0x20>;
				snps,refclk_fladj;
				snps,enable_guctl1_resume_quirk;
				snps,enable_guctl1_ipd_quirk;
				snps,xhci-stream-quirk;
				dr_mode = "host";
				snps,usb3_lpm_capable;
				phy-names = "usb3-phy";
				phys = <0x3a 0x4 0x0 0x2 0x18cba80>;
			};
		};

		usb1@ff9e0000 {
			#address-cells = <0x2>;
			#size-cells = <0x2>;
			status = "disabled";
			compatible = "xlnx,zynqmp-dwc3";
			reg = <0x0 0xff9e0000 0x0 0x100>;
			clock-names = "bus_clk", "ref_clk";
			power-domains = <0x3b>;
			ranges;
			nvmem-cells = <0x27>;
			nvmem-cell-names = "soc_revision";
			clocks = <0x3 0x21 0x3 0x22>;

			dwc3@fe300000 {
				compatible = "snps,dwc3";
				status = "disabled";
				reg = <0x0 0xfe300000 0x0 0x40000>;
				interrupt-parent = <0x4>;
				interrupts = <0x0 0x46 0x4 0x0 0x4a 0x4>;
				#stream-id-cells = <0x1>;
				iommus = <0xf 0x861>;
				snps,quirk-frame-length-adjustment = <0x20>;
				snps,refclk_fladj;
				snps,enable_guctl1_resume_quirk;
				snps,enable_guctl1_ipd_quirk;
				snps,xhci-stream-quirk;
			};
		};

		watchdog@fd4d0000 {
			compatible = "cdns,wdt-r1p2";
			status = "disabled";
			interrupt-parent = <0x4>;
			interrupts = <0x0 0x71 0x1>;
			reg = <0x0 0xfd4d0000 0x0 0x1000>;
			timeout-sec = <0xa>;
			clocks = <0x3 0x4b>;
		};

		ams@ffa50000 {
			compatible = "xlnx,zynqmp-ams";
			status = "okay";
			interrupt-parent = <0x4>;
			interrupts = <0x0 0x38 0x4>;
			interrupt-names = "ams-irq";
			reg = <0x0 0xffa50000 0x0 0x800>;
			reg-names = "ams-base";
			#address-cells = <0x2>;
			#size-cells = <0x2>;
			#io-channel-cells = <0x1>;
			ranges;
			clocks = <0x3 0x46>;

			ams_ps@ffa50800 {
				compatible = "xlnx,zynqmp-ams-ps";
				status = "okay";
				reg = <0x0 0xffa50800 0x0 0x400>;
			};

			ams_pl@ffa50c00 {
				compatible = "xlnx,zynqmp-ams-pl";
				status = "okay";
				reg = <0x0 0xffa50c00 0x0 0x400>;
			};
		};

		dp@fd4a0000 {
			compatible = "xlnx,v-dp";
			status = "disabled";
			reg = <0x0 0xfd4a0000 0x0 0x1000>;
			interrupts = <0x0 0x77 0x4>;
			interrupt-parent = <0x4>;
			clock-names = "aclk", "aud_clk";
			power-domains = <0x3c>;
			xlnx,dp-version = "v1.2";
			xlnx,max-lanes = <0x2>;
			xlnx,max-link-rate = <0x83d60>;
			xlnx,max-bpc = <0x10>;
			xlnx,enable-ycrcb;
			xlnx,colormetry = "rgb";
			xlnx,bpc = <0x8>;
			xlnx,audio-chan = <0x2>;
			xlnx,dp-sub = <0xb>;
			xlnx,max-pclock-frequency = <0x493e0>;
			clocks = <0x3d 0x3 0x11>;
			linux,phandle = <0xa>;
			phandle = <0xa>;
		};

		dp_sub@fd4aa000 {
			compatible = "xlnx,dp-sub";
			status = "disabled";
			reg = <0x0 0xfd4aa000 0x0 0x1000 0x0 0xfd4ab000 0x0 0x1000 0x0 0xfd4ac000 0x0 0x1000>;
			reg-names = "blend", "av_buf", "aud";
			xlnx,output-fmt = "rgb";
			xlnx,vid-fmt = "yuyv";
			xlnx,gfx-fmt = "rgb565";
			power-domains = <0x3c>;
			linux,phandle = <0xb>;
			phandle = <0xb>;
		};

		dma@fd4c0000 {
			compatible = "xlnx,dpdma";
			status = "disabled";
			reg = <0x0 0xfd4c0000 0x0 0x1000>;
			interrupts = <0x0 0x7a 0x4>;
			interrupt-parent = <0x4>;
			clock-names = "axi_clk";
			power-domains = <0x3c>;
			dma-channels = <0x6>;
			#dma-cells = <0x1>;
			clocks = <0x3 0x14>;
			linux,phandle = <0x9>;
			phandle = <0x9>;

			dma-video0channel {
				compatible = "xlnx,video0";
			};

			dma-video1channel {
				compatible = "xlnx,video1";
			};

			dma-video2channel {
				compatible = "xlnx,video2";
			};

			dma-graphicschannel {
				compatible = "xlnx,graphics";
			};

			dma-audio0channel {
				compatible = "xlnx,audio0";
			};

			dma-audio1channel {
				compatible = "xlnx,audio1";
			};
		};
	};

	fclk0 {
		status = "disabled";
		compatible = "xlnx,fclk";
		clocks = <0x3 0x47>;
	};

	fclk1 {
		status = "disabled";
		compatible = "xlnx,fclk";
		clocks = <0x3 0x48>;
	};

	fclk2 {
		status = "disabled";
		compatible = "xlnx,fclk";
		clocks = <0x3 0x49>;
	};

	fclk3 {
		status = "disabled";
		compatible = "xlnx,fclk";
		clocks = <0x3 0x4a>;
	};

	pss_ref_clk {
		u-boot,dm-pre-reloc;
		compatible = "fixed-clock";
		#clock-cells = <0x0>;
		clock-frequency = <0x1fca055>;
		linux,phandle = <0x3e>;
		phandle = <0x3e>;
	};

	video_clk {
		u-boot,dm-pre-reloc;
		compatible = "fixed-clock";
		#clock-cells = <0x0>;
		clock-frequency = <0x19bfcc0>;
		linux,phandle = <0x3f>;
		phandle = <0x3f>;
	};

	pss_alt_ref_clk {
		u-boot,dm-pre-reloc;
		compatible = "fixed-clock";
		#clock-cells = <0x0>;
		clock-frequency = <0x0>;
		linux,phandle = <0x40>;
		phandle = <0x40>;
	};

	gt_crx_ref_clk {
		u-boot,dm-pre-reloc;
		compatible = "fixed-clock";
		#clock-cells = <0x0>;
		clock-frequency = <0x66ff300>;
		linux,phandle = <0x42>;
		phandle = <0x42>;
	};

	aux_ref_clk {
		u-boot,dm-pre-reloc;
		compatible = "fixed-clock";
		#clock-cells = <0x0>;
		clock-frequency = <0x19bfcc0>;
		linux,phandle = <0x41>;
		phandle = <0x41>;
	};

	clkc {
		u-boot,dm-pre-reloc;
		#clock-cells = <0x1>;
		compatible = "xlnx,zynqmp-clkc";
		clocks = <0x3e 0x3f 0x40 0x41 0x42>;
		clock-names = "pss_ref_clk", "video_clk", "pss_alt_ref_clk", "aux_ref_clk", "gt_crx_ref_clk";
		clock-output-names = "iopll", "rpll", "apll", "dpll", "vpll", "iopll_to_fpd", "rpll_to_fpd", "apll_to_lpd", "dpll_to_lpd", "vpll_to_lpd", "acpu", "acpu_half", "dbf_fpd", "dbf_lpd", "dbg_trace", "dbg_tstmp", "dp_video_ref", "dp_audio_ref", "dp_stc_ref", "gdma_ref", "dpdma_ref", "ddr_ref", "sata_ref", "pcie_ref", "gpu_ref", "gpu_pp0_ref", "gpu_pp1_ref", "topsw_main", "topsw_lsbus", "gtgref0_ref", "lpd_switch", "lpd_lsbus", "usb0_bus_ref", "usb1_bus_ref", "usb3_dual_ref", "usb0", "usb1", "cpu_r5", "cpu_r5_core", "csu_spb", "csu_pll", "pcap", "iou_switch", "gem_tsu_ref", "gem_tsu", "gem0_ref", "gem1_ref", "gem2_ref", "gem3_ref", "gem0_tx", "gem1_tx", "gem2_tx", "gem3_tx", "qspi_ref", "sdio0_ref", "sdio1_ref", "uart0_ref", "uart1_ref", "spi0_ref", "spi1_ref", "nand_ref", "i2c0_ref", "i2c1_ref", "can0_ref", "can1_ref", "can0", "can1", "dll_ref", "adma_ref", "timestamp_ref", "ams_ref", "pl0", "pl1", "pl2", "pl3", "wdt";
		linux,phandle = <0x3>;
		phandle = <0x3>;
	};

	dp_aclk {
		compatible = "fixed-clock";
		#clock-cells = <0x0>;
		clock-frequency = <0x5f5e100>;
		clock-accuracy = <0x64>;
		linux,phandle = <0x3d>;
		phandle = <0x3d>;
	};

	gpio-keys {
		compatible = "gpio-keys";
		#address-cells = <0x1>;
		#size-cells = <0x0>;
		autorepeat;

		sw19 {
			label = "sw19";
			gpios = <0x1f 0x16 0x0>;
			linux,code = <0x6c>;
			gpio-key,wakeup;
			autorepeat;
		};
	};

	leds {
		compatible = "gpio-leds";

		heartbeat_led {
			label = "heartbeat";
			gpios = <0x1f 0x17 0x0>;
			linux,default-trigger = "heartbeat";
		};
	};

	amba_pl@0 {
		#address-cells = <0x2>;
		#size-cells = <0x2>;
		compatible = "simple-bus";
		ranges;

		axi_bram_ctrl@a0e00000 {
			compatible = "xlnx,axi-bram-ctrl-4.1";
			reg = <0x0 0xa0e00000 0x0 0x10000>;
			xlnx,bram-addr-width = <0xc>;
			xlnx,bram-inst-mode = "EXTERNAL";
			xlnx,ecc = <0x0>;
			xlnx,ecc-onoff-reset-value = <0x0>;
			xlnx,ecc-type = <0x0>;
			xlnx,fault-inject = <0x0>;
			xlnx,memory-depth = <0x1000>;
			xlnx,rd-cmd-optimization = <0x0>;
			xlnx,read-latency = <0x1>;
			xlnx,s-axi-ctrl-addr-width = <0x20>;
			xlnx,s-axi-ctrl-data-width = <0x20>;
			xlnx,s-axi-id-width = <0x1>;
			xlnx,s-axi-supports-narrow-burst = <0x1>;
			xlnx,select-xpm = <0x1>;
			xlnx,single-port-bram = <0x1>;
		};

		axi_drp_bridge@a0f00000 {
			compatible = "xlnx,axi-drp-bridge-181226";
			reg = <0x0 0xa0f00000 0x0 0x1000>;
		};

		axi_drp_bridge@a0060000 {
			compatible = "xlnx,axi-drp-bridge-181226";
			reg = <0x0 0xa0060000 0x0 0x2000>;
		};

		axi_drp_bridge@a0050000 {
			compatible = "xlnx,axi-drp-bridge-181226";
			reg = <0x0 0xa0050000 0x0 0x10000>;
		};

		axi_bram_ctrl@a1020000 {
			compatible = "xlnx,axi-bram-ctrl-4.1";
			reg = <0x0 0xa1020000 0x0 0x10000>;
			xlnx,bram-addr-width = <0xd>;
			xlnx,bram-inst-mode = "EXTERNAL";
			xlnx,ecc = <0x0>;
			xlnx,ecc-onoff-reset-value = <0x0>;
			xlnx,ecc-type = <0x0>;
			xlnx,fault-inject = <0x0>;
			xlnx,memory-depth = <0x2000>;
			xlnx,rd-cmd-optimization = <0x0>;
			xlnx,read-latency = <0x1>;
			xlnx,s-axi-ctrl-addr-width = <0x20>;
			xlnx,s-axi-ctrl-data-width = <0x20>;
			xlnx,s-axi-id-width = <0x1>;
			xlnx,s-axi-supports-narrow-burst = <0x1>;
			xlnx,select-xpm = <0x1>;
			xlnx,single-port-bram = <0x1>;
		};

		axi_bram_ctrl@a1010000 {
			compatible = "xlnx,axi-bram-ctrl-4.1";
			reg = <0x0 0xa1010000 0x0 0x1000>;
			xlnx,bram-addr-width = <0xa>;
			xlnx,bram-inst-mode = "EXTERNAL";
			xlnx,ecc = <0x0>;
			xlnx,ecc-onoff-reset-value = <0x0>;
			xlnx,ecc-type = <0x0>;
			xlnx,fault-inject = <0x0>;
			xlnx,memory-depth = <0x400>;
			xlnx,rd-cmd-optimization = <0x0>;
			xlnx,read-latency = <0x1>;
			xlnx,s-axi-ctrl-addr-width = <0x20>;
			xlnx,s-axi-ctrl-data-width = <0x20>;
			xlnx,s-axi-id-width = <0x1>;
			xlnx,s-axi-supports-narrow-burst = <0x1>;
			xlnx,select-xpm = <0x1>;
			xlnx,single-port-bram = <0x1>;
		};

		debug_bridge@a0d00000 {
			compatible = "xlnx,debug-bridge-3.0";
			reg = <0x0 0xa0d00000 0x0 0x10000>;
			xlnx,bscan-mux = <0x1>;
			xlnx,build-revision = <0x0>;
			xlnx,chip-id = <0x0>;
			xlnx,clk-input-freq-hz = <0x11e1a300>;
			xlnx,core-major-ver = <0x1>;
			xlnx,core-minor-alpha-ver = <0x61>;
			xlnx,core-minor-ver = <0x0>;
			xlnx,core-type = <0x1>;
			xlnx,dclk-has-reset = <0x0>;
			xlnx,debug-mode = <0x3>;
			xlnx,design-type = <0x0>;
			xlnx,device-family = <0x0>;
			xlnx,en-bscanid-vec = "false";
			xlnx,en-int-sim = <0x1>;
			xlnx,en-passthrough = <0x0>;
			xlnx,enable-clk-divider = "false";
			xlnx,fifo-style = "SUBCORE";
			xlnx,ir-id-instr = <0x0>;
			xlnx,ir-user1-instr = <0x0>;
			xlnx,ir-width = <0x0>;
			xlnx,major-version = <0xe>;
			xlnx,master-intf-type = <0x1>;
			xlnx,minor-version = <0x1>;
			xlnx,num-bs-master = <0x0>;
			xlnx,pcie-ext-cfg-base-addr = <0x400>;
			xlnx,pcie-ext-cfg-next-ptr = <0x0>;
			xlnx,pcie-ext-cfg-vsec-id = <0x8>;
			xlnx,pcie-ext-cfg-vsec-length = <0x20>;
			xlnx,pcie-ext-cfg-vsec-rev-id = <0x0>;
			xlnx,tck-clock-ratio = <0x8>;
			xlnx,two-prim-mode = "false";
			xlnx,use-bufr = <0x0>;
			xlnx,use-ext-bscan = "true";
			xlnx,use-softbscan = <0x1>;
			xlnx,use-startup-clk = "false";
			xlnx,user-scan-chain = <0x1>;
			xlnx,xsdb-num-slaves = <0x0>;
			xlnx,xvc-hw-id = <0x1>;
			xlnx,xvc-sw-id = <0x1>;
		};

		axi_quad_spi@a0020000 {
			bits-per-word = <0x8>;
			compatible = "xlnx,xps-spi-2.00.a";
			fifo-size = <0x10>;
			interrupt-parent = <0x4>;
			interrupts = <0x0 0x69 0x1>;
			num-cs = <0x1>;
			reg = <0x0 0xa0020000 0x0 0x1000>;
			xlnx,num-ss-bits = <0x1>;
			xlnx,spi-mode = <0x2>;
		};

		timer@a0010000 {
			clock-frequency = <0x17d7840>;
			clocks = <0x43>;
			compatible = "xlnx,xps-timer-1.00.a";
			reg = <0x0 0xa0010000 0x0 0x1000>;
			xlnx,count-width = <0x20>;
			xlnx,gen0-assert = <0x1>;
			xlnx,gen1-assert = <0x1>;
			xlnx,one-timer-only = <0x1>;
			xlnx,trig0-assert = <0x1>;
			xlnx,trig1-assert = <0x1>;
		};

		axi-pcie@b0000000 {
			#address-cells = <0x3>;
			#interrupt-cells = <0x1>;
			#size-cells = <0x2>;
			compatible = "xlnx,xdma-host-3.00";
			device_type = "pci";
			interrupt-map = <0x0 0x0 0x0 0x1 0x44 0x1 0x0 0x0 0x0 0x2 0x44 0x2 0x0 0x0 0x0 0x3 0x44 0x3 0x0 0x0 0x0 0x4 0x44 0x4>;
			interrupt-map-mask = <0x0 0x0 0x0 0x7>;
			ranges = <0x2000000 0x0 0x0 0x0 0xb0000000 0x0 0x2000000>;
			reg = <0x0 0xbc000000 0x0 0x200000>;

			interrupt-controller {
				#address-cells = <0x0>;
				#interrupt-cells = <0x1>;
				interrupt-controller;
				linux,phandle = <0x44>;
				phandle = <0x44>;
			};
		};

		myremap_lockID@bc000000 {
			compatible = "xlnx,myremap-lockID-181226";
			reg = <0x0 0xbc000000 0x0 0x200000>;
			xlnx,addr-remap-default = <0x0>;
			xlnx,addrstatic-width = <0xb>;
			xlnx,axi-cntr-addr-width = <0x4>;
			xlnx,axi-cntr-data-width = <0x20>;
			xlnx,m00-axi-addr-width = <0x20>;
			xlnx,m00-axi-aruser-width = <0x5>;
			xlnx,m00-axi-awuser-width = <0x5>;
			xlnx,m00-axi-buser-width = <0x0>;
			xlnx,m00-axi-data-width = <0x20>;
			xlnx,m00-axi-id-width = <0x1>;
			xlnx,s00-axi-addr-width = <0x20>;
			xlnx,s00-axi-aruser-width = <0x0>;
			xlnx,s00-axi-awuser-width = <0x0>;
			xlnx,s00-axi-buser-width = <0x0>;
			xlnx,s00-axi-data-width = <0x20>;
			xlnx,s00-axi-id-width = <0x4>;
		};

		PERIPHERAL@ff380000 {
			compatible = "xlnx,PERIPHERAL-1.0";
			reg = <0x0 0xff380000 0x0 0x80000>;
		};

		PERIPHERAL@ff990000 {
			compatible = "xlnx,PERIPHERAL-1.0";
			reg = <0x0 0xff990000 0x0 0x10000>;
		};

		misc_clk_0 {
			#clock-cells = <0x0>;
			clock-frequency = <0x17d7840>;
			compatible = "fixed-clock";
			linux,phandle = <0x43>;
			phandle = <0x43>;
		};

		uio_reg_hpm0_cnt@A0000000 {
			compatible="generic-uio";
			reg = <0x0 0xA0000000 0x0 0x01000000>;
			interrupts = <0 0>;
		};

		uio_reg_hpm1_trx1@B0000000 {
			compatible="generic-uio";
			reg = <0x0 0xB0000000 0x0 0x02000000>;
			interrupts = <0 0>;
		};
		uio_reg_hpm0_eth@A1000000 {
			compatible="generic-uio";
			reg = <0x0 0xA1000000 0x0 0x01000000>;
			interrupts = <0 0>;
		};
		uio_reg_hpm0_phyl@A2000000 {
			compatible="generic-uio";
			reg = <0x0 0xA2000000 0x0 0x01000000>;
			interrupts = <0 0>;
		};
		uio_reg_hpm0_phyl@A3000000 {
			compatible="generic-uio";
			reg = <0x0 0xA3000000 0x0 0x01000000>;
			interrupts = <0 0>;
		};
		uio_reg_hpm0_phyl@A4000000 {
			compatible="generic-uio";
			reg = <0x0 0xA4000000 0x0 0x01000000>;
			interrupts = <0 0>;
		};
		uio_reg_hpm1_pcie@BC000000 {
			compatible="generic-uio";
			reg = <0x0 0xBC000000 0x0 0x01000000>;
			interrupts = <0 0>;
		};
		uio_reg_cpu@FF000000 {
			compatible="generic-uio";
			reg = <0x0 0xFF000000 0x0 0x00C00000>;
			interrupts = <0 0>;
		};

		uio_reg_wdt_cnt@FD4D0000 {
			compatible="generic-uio";
			reg = <0x0 0xFD4D0000 0x0 0x1000>;
			interrupts = <0 0>;
		};

		uio_reg_pcie_root@E0000000 {
			compatible="generic-uio";
			reg = <0x0 0xE0000000 0x0 0x00100000>;
			interrupts = <0 0>;
		};
		uio_reg_pcie_endp@E0100000 {
			compatible="generic-uio";
			reg = <0x0 0xE0100000 0x0 0x00100000>;
			interrupts = <0 0>;
		};

		uio_irq_wdt@00000000 {
			compatible="generic-uio";
			reg = <0x0 0xA0000000 0x0 0x00001000>;
			interrupt-parent = <0x4>;
			interrupts = <0x0 89 0x4>;
		};

		uio_irq_1s@00000000 {
			compatible="generic-uio";
			reg = <0x0 0xA0000000 0x0 0x00001000>;
			interrupt-parent = <0x4>;
			interrupts = <0x0 90 0x1>;
		};

		uio_irq_1pps@00000000 {
			compatible="generic-uio";
			reg = <0x0 0xA0000000 0x0 0x00001000>;
			interrupt-parent = <0x4>;
			interrupts = <0x0 91 0x1>;
		};
		
		uio_irq_sv@00000000 {
			compatible="generic-uio";
			reg = <0x0 0xA0000000 0x0 0x00001000>;
			interrupt-parent = <0x4>;
			interrupts = <0x0 92 0x1>;
		};

		uio_irq_fheth0mac@00000000 {
			compatible="generic-uio";
			reg = <0x0 0xA1000000 0x0 0x00001000>;
			interrupt-parent = <0x4>;
			interrupts = <0x0 108 0x4>;
		};

	};

	chosen {
		bootargs = "console=ttyPS0,115200 earlycon clk_ignore_unused uio_pdrv_genirq.of_id=generic-uio";
		stdout-path = "serial0:115200n8";
	};

	aliases {
		ethernet0 = "/amba/ethernet@ff0b0000";
		serial0 = "/amba/serial@ff010000";
		spi0 = "/amba_pl@0/axi_quad_spi@a0020000";
		spi1 = "/amba/spi@ff0f0000";
		spi2 = "/amba/spi@ff040000";
		spi3 = "/amba/spi@ff050000";
	};

	memory {
		device_type = "memory";
		reg = <0x0 0x0 0x0 0x80000000>;
	};
};
